# CPSW0_NUSS_SGMII register map
Vendor: Texas Instruments
Peripheral module from a debugger description file (folder J7VCL).
Registers are 32-bit, read-write, reset 0x0 unless marked. A register's access mark holds for its fields unless they carry their own. Offsets are as the file gives them; lines under a group give offsets from that group; [hi:lo] are bit positions; {n}, {i} and the like mark numbered series; 'fields as' and 'values as' point back to an identical list; <NAME> marks a mode.

## CPSW0_NUSS_SGMII
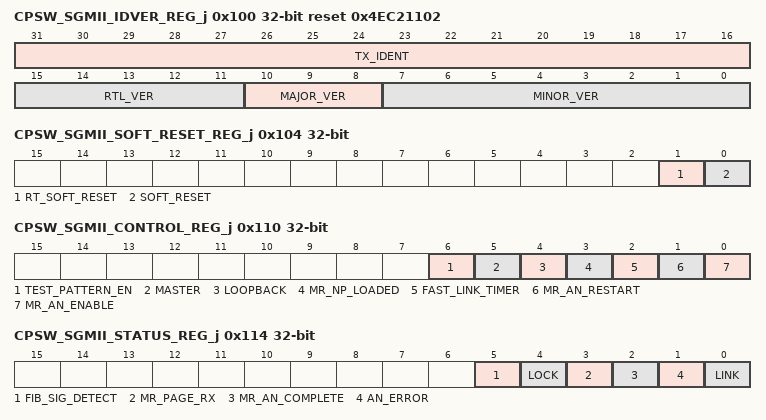
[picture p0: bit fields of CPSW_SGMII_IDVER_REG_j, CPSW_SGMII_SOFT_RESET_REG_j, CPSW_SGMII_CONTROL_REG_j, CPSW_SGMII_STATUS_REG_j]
0x100 CPSW_SGMII_IDVER_REG_j ro reset 0x4EC21102 — SGMII IDVER register. Offset = 100h + (j * 100h); where j = 0h to 7h.
  [31:16] TX_IDENT — MODULE value
  [15:11] RTL_VER — RTL version value
  [10:8] MAJOR_VER — Major version value
  [7:0] MINOR_VER — Minor version value
0x104 CPSW_SGMII_SOFT_RESET_REG_j — SGMII Soft Reset Register. Offset = 104h + (j * 100h); where j = 0h to 7h.
  [1] RT_SOFT_RESET — Transmit and Receive Software Reset.This bit is intended to be used when changing between loopback mode and normal mode of operation.
  [0] SOFT_RESET — Software Reset.
0x110 CPSW_SGMII_CONTROL_REG_j — SGMII Control Register Offset = 110h + (j * 100h); where j = 0h to 7h.
  [6] TEST_PATTERN_EN — Test Pattern Enable.
  [5] MASTER — Master Mode.
  [4] LOOPBACK — Loopback mode.
  [3] MR_NP_LOADED — Next Page Loaded.
  [2] FAST_LINK_TIMER
  [1] MR_AN_RESTART — Auto Negotiation Restart.
  [0] MR_AN_ENABLE — Auto Negotiation Enable.
0x114 CPSW_SGMII_STATUS_REG_j ro — SGMII Status Register Offset = 114h + (j * 100h); where j = 0h to 7h.
  [5] FIB_SIG_DETECT — Fiber Signal Detect.
  [4] LOCK
  [3] MR_PAGE_RX — Next Page Received.
  [2] MR_AN_COMPLETE — Auto negotiation complete.
  [1] AN_ERROR — Auto negotiation error.
  [0] LINK — Link indicator.
0x118 CPSW_SGMII_MR_ADV_ABILITY_REG_j — SGMII MR Advertized Ability Register. Offset = 118h + (j * 100h); where j = 0h to 7h.
  [15:0] MR_ADV_ABILITY — Advertised Ability.
0x11C CPSW_SGMII_MR_NP_TX_REG_j — SGMII Next Pate Transmit Register. Offset = 11Ch + (j * 100h); where j = 0h to 7h.
  [15:0] MR_NP_TX — Next Page Transmit.
0x120 CPSW_SGMII_MR_LP_ADV_ABILITY_REG_j ro — SGMII Link Partner Advertized Ability Register. Offset = 120h + (j * 100h); where j = 0h to 7h.
  [15:0] MR_LP_ADV_ABILITY — Link Partner Advertised Ability.
0x124 CPSW_SGMII_MR_LP_NP_RX_REG_j ro — SGMII Link Partner Next Page Receive Register Offset = 124h + (j * 100h); where j = 0h to 7h.
  [15:0] MR_LP_NP_RX — Link Partner Next Page Received.
0x130 CPSW_SGMII_TX_CFG_REG_j — SGMII Transmit Configuration Register Offset = 130h + (j * 100h); where j = 0h to 7h.
  [31:0] TX_CFG — Transmit configuration register output
0x134 CPSW_SGMII_RX_CFG_REG_j — SGMII Receive Configuration Register Offset = 134h + (j * 100h); where j = 0h to 7h.
  [31:0] RX_CFG — Receive configuration register output
0x138 CPSW_SGMII_AUX_CFG_REG_j — SGMII Auxiliary Configuration Register. Offset = 138h + (j * 100h); where j = 0h to 7h.
  [31:0] AUX_CFG — Auxiliary configuration register output
0x140 CPSW_SGMII_DIAG_CLEAR_REG_j — SGMII Diagnostics Clear Register Offset = 140h + (j * 100h); where j = 0h to 7h
  [0] DIAG_CLEAR — Diagnostics Clear.
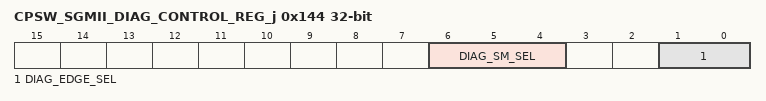
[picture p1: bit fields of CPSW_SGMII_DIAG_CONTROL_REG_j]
0x144 CPSW_SGMII_DIAG_CONTROL_REG_j — SGMII Diagnostics Control Register Offset = 144h + (j * 100h); where j = 0h to 7h.
  [6:4] DIAG_SM_SEL — Diagnostic Select.
  [1:0] DIAG_EDGE_SEL — Diagnostis Hold Signals Edge Select
0x148 CPSW_SGMII_DIAG_STATUS_REG_j ro — SGMII Diagnostics Status Register Offset = 148h + (j * 100h); where j = 0h to 7h.
  [15:0] DIAG_STATUS — Diagnostics status.
